# STM32U5A5xx register map
File version: 1.0
Registers are 32-bit, read-write, reset 0x0 unless marked. A register's access mark holds for its fields unless they carry their own. Offsets are from the block's base; [hi:lo] are bit positions; {n}, {i} and the like mark numbered series; 'fields as' and 'values as' point back to an identical list.

## ICACHE — Instruction Cache
Base 0x40030400
Same registers: ICACHE_S 0x50030400
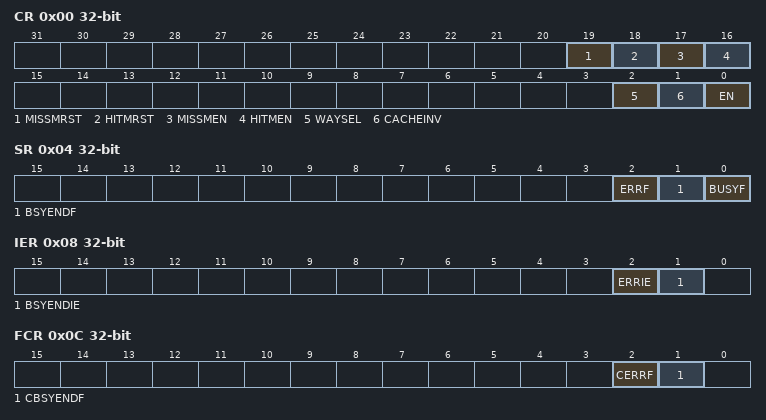
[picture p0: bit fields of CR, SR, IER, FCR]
0x00 CR — ICACHE control register
  [19] MISSMRST — Miss monitor reset
  [18] HITMRST — Hit monitor reset
  [17] MISSMEN — Miss monitor enable
  [16] HITMEN — Hit monitor enable
  [2] WAYSEL — Ways selection
    0=ICACHE_1WAY (1-way cache (direct mapped cache)); 1=ICACHE_2WAYS (2-ways set associative cache (default))
  [1] CACHEINV — Cache invalidation
  [0] EN — Enable
0x04 SR — ICACHE status register
  [2] ERRF — Cache error flag
  [1] BSYENDF — Busy end flag
  [0] BUSYF — Busy flag
0x08 IER — ICACHE interrupt enable register
  [2] ERRIE — Cache error interrupt enable
  [1] BSYENDIE — Busy end interrupt enable
0x0C FCR — ICACHE Flag clear register
  [2] CERRF — Cache error flag clear
  [1] CBSYENDF — Busy end flag clear
0x10 HMONR — ICACHE hit monitor register
  [31:0] HITMON — Cache hit monitor register
0x14 MMONR — ICACHE miss monitor register
  [15:0] MISSMON — Cache miss monitor register
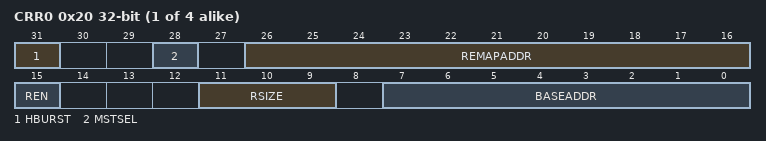
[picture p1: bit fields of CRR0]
{0x20+4i} CRR{i} (i=0..3) — ICACHE region {i} configuration register
  [31] HBURST — Region X output burst type
  [28] MSTSEL — Region X AHB cache master selection
  [26:16] REMAPADDR — Remap address of Region X to be remapped
  [15] REN — Region X enable
  [11:9] RSIZE — Region X size
  [7:0] BASEADDR — Base address of region X to remap

## DCACHE1 — Data Cache
Base 0x40031400
Same registers: DCACHE1_S 0x50031400
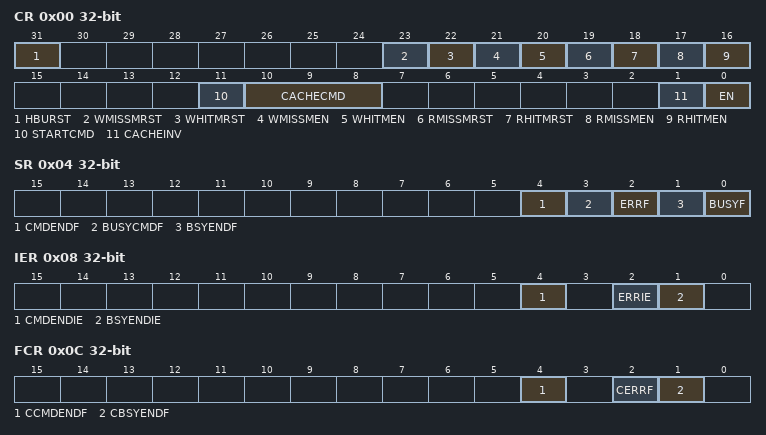
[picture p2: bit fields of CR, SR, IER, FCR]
0x00 CR — DCACHE control register
  [31] HBURST — Read burst type
    0=WRAP; 1=INCR
  [23] WMISSMRST — Write Miss monitor reset
  [22] WHITMRST — Write Hit monitor reset
  [21] WMISSMEN — Write Miss monitor enable
  [20] WHITMEN — Write Hit monitor enable
  [19] RMISSMRST — Read Miss monitor reset
  [18] RHITMRST — Read Hit monitor reset
  [17] RMISSMEN — Read Miss monitor enable
  [16] RHITMEN — Read Hit monitor enable
  [11] STARTCMD — Start command
  [10:8] CACHECMD — Cache command
    2=INVALIDATE_BY_ADDR; 1=CLEAN_BY_ADDR; 3=CLEAN_INVALIDATE_BY_ADDR; 0=NO_OPERATION
  [1] CACHEINV — Cache invalidation
  [0] EN — Enable
0x04 SR — DCACHE status register
  [4] CMDENDF — Command end flag
  [3] BUSYCMDF — Busy command flag
  [2] ERRF — Cache error flag
  [1] BSYENDF — Busy end flag
  [0] BUSYF — Busy flag
0x08 IER — DCACHE interrupt enable register
  [4] CMDENDIE — Command end interrupt enable
  [2] ERRIE — Cache error interrupt enable
  [1] BSYENDIE — Busy end interrupt enable
0x0C FCR — DCACHE Flag clear register
  [4] CCMDENDF — Command end flag clear
  [2] CERRF — Cache error flag clear
  [1] CBSYENDF — Busy end flag clear
0x10 RHMONR — DCACHE Read hit monitor register
  [31:0] RHITMON — Cache Read hit monitor register
0x14 RMMONR — DCACHE Read miss monitor register
  [15:0] RMISSMON — Cache Read miss monitor register
0x20 WHMONR — DCACHE Write hit monitor register
  [31:0] WHITMON — Cache Read hit monitor register
0x24 WMMONR — DCACHE Write miss monitor register
  [15:0] WMISSMON — Cache Read miss monitor register
0x28 CMDRSADDRR — DCACHE Command Start Address register
  [31:5] CMDSTARTADDR — Command start address
0x2C CMDREADDRR — DCACHE Command End Address register
  [31:5] CMDENDADDR — Command end address

## GTZC_TZSC1 — Global TrustZone Controller
Base 0x40032400
Same registers: GTZC_TZSC1_S 0x50032400
0x00 CR — TZSC control register
  [0] LCK
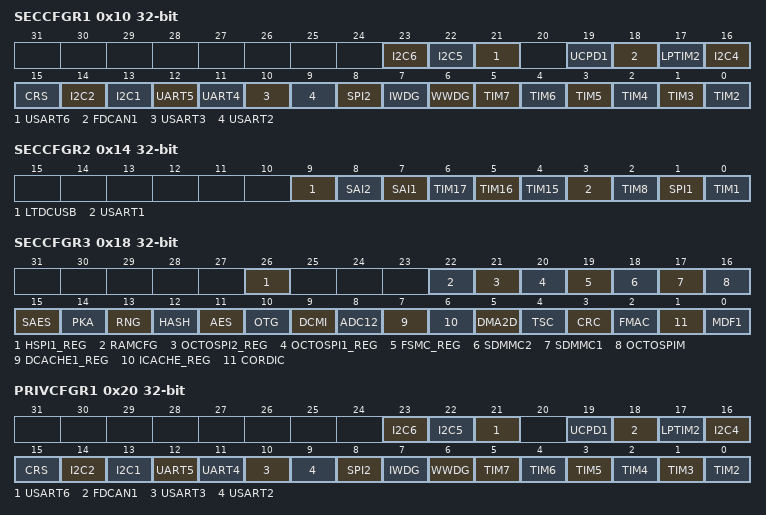
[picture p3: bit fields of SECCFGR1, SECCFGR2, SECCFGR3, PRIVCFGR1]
0x10 SECCFGR1 — TZSC secure configuration register 1
  [23] I2C6, [22] I2C5, [21] USART6, [19] UCPD1, [18] FDCAN1, [17] LPTIM2, [16] I2C4, [15] CRS, [14] I2C2, [13] I2C1, [12] UART5, [11] UART4, [10] USART3, [9] USART2, [8] SPI2, [7] IWDG, [6] WWDG, [n-2] TIM{n} (n=2..7)
0x14 SECCFGR2 — TZSC secure configuration register 2
  [9] LTDCUSB, [8] SAI2, [7] SAI1, [6] TIM17, [5] TIM16, [4] TIM15, [3] USART1, [2] TIM8, [1] SPI1, [0] TIM1
0x18 SECCFGR3 — TZSC secure configuration register 3
  [26] HSPI1_REG, [22] RAMCFG, [21] OCTOSPI2_REG, [20] OCTOSPI1_REG, [19] FSMC_REG, [18] SDMMC2, [17] SDMMC1, [16] OCTOSPIM, [15] SAES, [14] PKA, [13] RNG, [12] HASH, [11] AES, [10] OTG, [9] DCMI, [8] ADC12, [7] DCACHE1_REG, [6] ICACHE_REG, [5] DMA2D, [4] TSC, [3] CRC, [2] FMAC, [1] CORDIC, [0] MDF1
0x20 PRIVCFGR1 — TZSC privilege configuration register 1
  fields as SECCFGR1
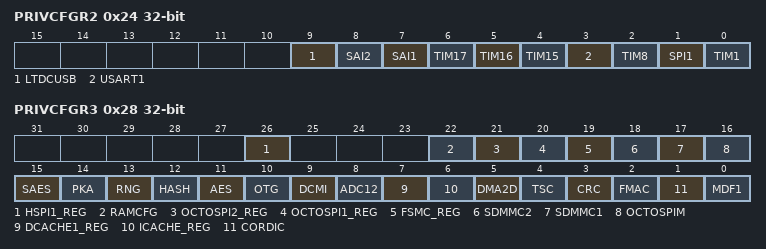
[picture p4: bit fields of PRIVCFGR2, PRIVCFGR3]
0x24 PRIVCFGR2 — TZSC privilege configuration register 2
  fields as SECCFGR2
0x28 PRIVCFGR3 — TZSC privilege configuration register 3
  fields as SECCFGR3
{0x30+0x10*i} MPCWM{i}ACFGR (i=1..6) — TZSC memory {i} sub-region A watermark configuration register
{0x34+0x10*i} MPCWM{i}AR (i=1..6) — TZSC memory {i} sub-region A watermark register
0x48 MPCWM1BCFGR — TZSC memory 1 sub-region B watermark configuration register
0x4C MPCWM1BR — TZSC memory 1 sub-region B watermark register
0x58 MPCWM2BCFGR — TZSC memory 2 sub-region B watermark configuration register
0x5C MPCWM2BR — TZSC memory 2 sub-region B watermark register
0x88 MPCWM5BCFGR — TZSC memory 5 sub-region B watermark configuration register
0x8C MPCWM5BR — TZSC memory 5 sub-region B watermark register
0x98 MPCWM6BCFGR — TZSC memory 6 sub-region B watermark configuration register
0x9C MPCWM6BR — TZSC memory 6 sub-region B watermark register

## GTZC_TZSC2 — Global TrustZone Controller
Base 0x46023000
Same registers: GTZC_TZSC2_S 0x56023000
Registers as GTZC_TZSC1; these are added or differ:
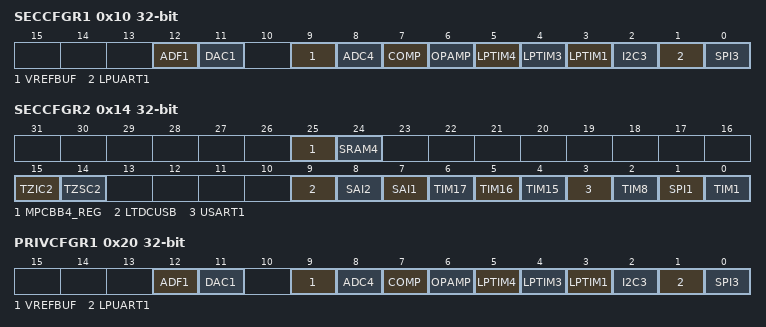
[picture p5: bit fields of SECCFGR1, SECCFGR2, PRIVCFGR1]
0x10 SECCFGR1 — TZSC secure configuration register 1
  [12] ADF1, [11] DAC1, [9] VREFBUF, [8] ADC4, [7] COMP, [6] OPAMP, [5] LPTIM4, [4] LPTIM3, [3] LPTIM1, [2] I2C3, [1] LPUART1, [0] SPI3
0x14 SECCFGR2 — TZSC secure configuration register 2
  [25] MPCBB4_REG, [24] SRAM4, [15] TZIC2, [14] TZSC2, [9] LTDCUSB, [8] SAI2, [7] SAI1, [6] TIM17, [5] TIM16, [4] TIM15, [3] USART1, [2] TIM8, [1] SPI1, [0] TIM1
0x20 PRIVCFGR1 — TZSC privilege configuration register 1
  fields as SECCFGR1
0x24 PRIVCFGR2 — TZSC privilege configuration register 2
0x28 PRIVCFGR3 — TZSC privilege configuration register 3
